# CCG2 register map
File version: 1.0
CPU: CM0 r1p0, little endian, no MPU, no FPU, 2 interrupt priority bits
Registers are 32-bit, read-write, reset 0x0 unless marked. A register's access mark holds for its fields unless they carry their own. Offsets are from the block's base; [hi:lo] are bit positions; {n}, {i} and the like mark numbered series; 'fields as' and 'values as' point back to an identical list; <NAME> marks a mode.

## USBPD (part 1 of 2)
Base 0x40080000
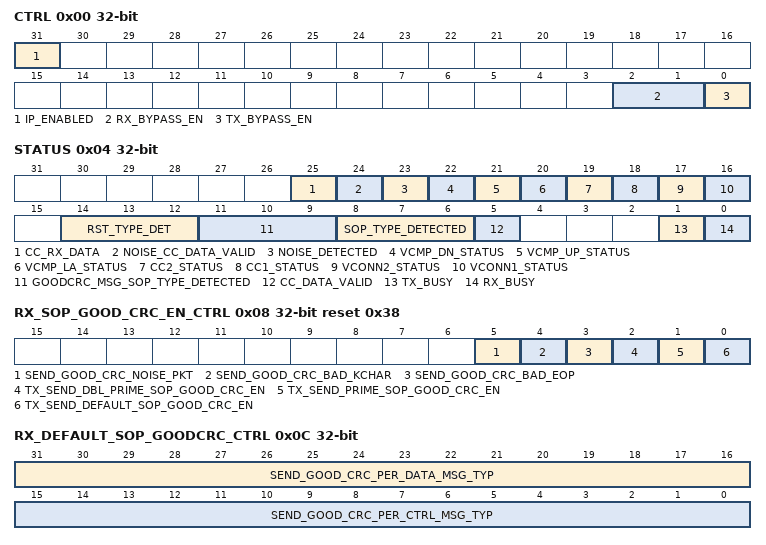
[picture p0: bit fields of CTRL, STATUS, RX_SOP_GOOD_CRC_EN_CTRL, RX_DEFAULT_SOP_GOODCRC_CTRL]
0x00 CTRL — Generic control register.
  [31] IP_ENABLED — IP enabled ('1') or not ('0'). "0" Resets the IP. The reset is an async reset. Note that when the IP is disabled, all the interrupt sources are also disabled.
  [2:1] RX_BYPASS_EN — Setting this register will bypass 5b/4b, CRC.
    0=NO_BYPASS; 1=RX_SOP_ALLIGN; 2=NO_RX_SOP_ALLGN
  [0] TX_BYPASS_EN — Setting this register will bypass 5b/4b, CRC.
0x04 STATUS — Generic status register.
  [25] CC_RX_DATA ro — This status bit shows the RX Data comparator output from s8usbpd_cc_top.
  [24] NOISE_CC_DATA_VALID ro — This status bit shows the CC_RX_VALID signal with the noise_detected signal effect. It is raw_cc_rx_valid & !noise_detected.
  [23] NOISE_DETECTED ro — This status shows the noise detection on vcmp_up or vcmp_la or CC RX Line. The source of noise from the comparator is selectable by RX_CC: VCMP_UP_COMP_ENABLE, VCMP_LA_COMP_ENABLE and RX_NOISE_CHECK_ENABLE. The Noise detectition is defined by NOISE_EDGE_COUNT
  [22] VCMP_DN_STATUS ro — This register provides the status of VCMP_DN (wakeup interrupt from deepsleep). Not enabled unless CMP_EN bit is set. Edge: Ra/Rd value changed OR Edge: Rp value changed
  [21] VCMP_UP_STATUS ro — This register provides the status of VCMP_UP (wakeup interrupt from deepsleep). Not enabled unless CMP_EN bit is set. Edge: Ra/Rd value changed {VCMP_UP, VCMP_DN}: 00: Ra connected 01: Rd connected 11: Nothing connected (float) OR Edge: Rp value changed {VCMP_UP, VCMP_DN}: 00: Default Rp broadcast 01: 1.5A Rp broadcast 11: 3.0A Rp broadcast
  [20] VCMP_LA_STATUS ro — This register provides the status CC_LINE_ACTIVITY (wakeup interrupt from deepsleep).
  [19] CC2_STATUS ro — CC2 status (wakeup interrupt from deepsleep) 1: CC2 attached 0: CC2 detached
  [18] CC1_STATUS ro — CC1 status (wakeup interrupt from deepsleep) 1: CC1 attached 0: CC1 detached
  [17] VCONN2_STATUS ro — The status of either vconn2_changed or cmp_out depending on the selection defined in DEBUG_CC_0.VCONN2_CMP_OUT_SEL VCONN2 status/cmp_out (wakeup interrupt from deepsleep) If VCONN2_CMP_SEL = 0 1: VCONN1 > 2.7V 0: VCONN1 < 2.7V If VCONN2_CMP_SEL = 0 1: cmp_out is 1 0: cmp_out is 0
  [16] VCONN1_STATUS ro — VCONN1 status (wakeup interrupt from deepsleep) 1: VCONN1 > 2.7V 0: VCONN1 < 2.7V
  [14:12] RST_TYPE_DET ro — RST Type detected:
    1=HARD_RESET_RCVD; 2=CABLE_RESET_RCVD; 3=RSVD1_RESET_RCVD; 4=RSVD2_RESET_RCVD
  [11:9] GOODCRC_MSG_SOP_TYPE_DETECTED ro — GoodCrc Message SOP type detected: At the start of every packet, INTR.RCV_GOODCRC_MSG_COMPLETE status is evaluated, if its reset, then this register will be updated with the new packet SOP value.
    0=NO_SOP_GOODCRC_RCVD; 1=DEFAULT_SOP_GOODCRC_RCVD; 2=PRIME_SOP_GOODCRC_RCVD; 3=DBL_PRIME_SOP_GOODCRC_RCVD; 4=DBG_PRIME_SOP_GOODCRC_RCVD; 5=DBG_DBL_PRIME_SOP_GOODCRC_RCVD; 6=RSVD1_SOP_GOODCRC_RCVD; 7=RSVD2_SOP_GOODCRC_RCVD
  [8:6] SOP_TYPE_DETECTED ro — Type of SOP detected for the packet stored in the RX SRAM: At the start of every packet, INTR.RCV_PACKET_COMPLETE and INTR.RCV_RST status is evaluated. If both are "0", then this register will be updated with the new packet SOP value. There is no clearing option.
    0=NO_SOP_RCVD; 1=DEFAULT_SOP_RCVD; 2=PRIME_SOP_RCVD; 3=DBL_PRIME_SOP_RCVD; 4=DBG_PRIME_SOP_RCVD; 5=DBG_DBL_PRIME_SOP_RCVD; 6=RSVD1_SOP_RCVD; 7=RSVD2_SOP_RCVD
  [5] CC_DATA_VALID ro — This status bit shows the CC_RX_VALID signal without noise_detected signal. This is the output of the RX comparator and it is not qualified with noise detection logic. 0: No Valid data on the CC line' 1: Valid Data detectd on the CC line
  [1] TX_BUSY ro — Transmitter is currently transmitting a packet or the crc timmer is running
  [0] RX_BUSY ro — Receiver is currently receiving a packet
0x08 RX_SOP_GOOD_CRC_EN_CTRL reset 0x38 — RX SOP Control for sending GoodCRC Message Hardware will wait for programmable IDLE_COUNTER and then send Good Crc Message.
  [5] SEND_GOOD_CRC_NOISE_PKT — Setting this bit will enable sending GoodCrcMsg for packet that has noise during the whole packet. This should be left to default for normal operation.
  [4] SEND_GOOD_CRC_BAD_KCHAR — Setting this bit will enable sending GoodCrcMsg for packet with KCHAR Error. This should be left to default for normal operation.
  [3] SEND_GOOD_CRC_BAD_EOP — Setting this bit will enable sending GoodCrcMsg for packet with Bad EOP. This should be left to default for normal operation.
  [2] TX_SEND_DBL_PRIME_SOP_GOOD_CRC_EN — Setting this bit will enable the TX block to automatically issue a GoodCRC Message when the received packet with dbl prime SOP which has no CRC issue and the packet has been written into SRAM successfully.
  [1] TX_SEND_PRIME_SOP_GOOD_CRC_EN — Setting this bit will enable the TX block to automatically issue a GoodCRC Message when the received packet with prime SOP which has no CRC issue and the packet has been written into SRAM successfully.
  [0] TX_SEND_DEFAULT_SOP_GOOD_CRC_EN — Setting this bit will enable the TX block to automatically issue a GoodCRC Message when the received packet with Dafault SOP which has no CRC issue and the packet has been written into SRAM successfully.
0x0C RX_DEFAULT_SOP_GOODCRC_CTRL — RX Default SOP GoodCRC Control There are two purposes for this register: 1. Transmit Path: When hardware is done transmitting a packet, it will start the RX_CRC_TIMER. The CRC timer should stop on following conditions: 1. Good CRC Received: With Matching Message ID, Matching Header Sop type. 2. Hard Reset on Receive side 3. Soft Reset on Receive Side: 4. Any other message legal in the current firmware state: Condition 1, condition 2: These two conditions are automatically taken care by hardware and CRC timer is stopped. Condition 3, condition 4: Firmware needs to take care of. Firmware can program what legal messages it is expecting in a particular state and hardware will stop its counter. E.G: If firmware wants the transmit logic to stop its CRC counter and not retry the packet on reception of these following messages: � Soft Reset Control Message: Message Type 1101 � Get Source Cap Control Message: Message Type 0111 � Vendor Defined Data Message: Message Type 1111 Then in that case firmware will program RX_DEFAULT_SOP_GOODCRC_CTRL to: 8000_2080 (Bit 7th, bit 13th and bit 31st) Hardware will stop the timers on reception of these packets and will also automatically send GoodCRC message to these messages if the proper auto bit is set in RX_SOP_GOOD_CRC_EN_CTRL. Other messages received will be logged in RX_Memory but Good CRC will not be returned or timer will not be stopped. 2. Receive Path: Based on one hot encoding of RX_DEFAULT_SOP_GOODCRC_CTRL mapped to message type field in the incoming header, Good CRC will be returned automatically if the correct RX_SOP_GOOD_CRC_EN_CTRL bit is set.
  [31:16] SEND_GOOD_CRC_PER_DATA_MSG_TYP — The Message type of a data message is a 4-bit field. Every bit of this register mapps to the data message types. CPU can used this register to select for which one of the the message types of a data message should hardware send a GOODCRC message.
  [15:0] SEND_GOOD_CRC_PER_CTRL_MSG_TYP — The Message type of a control message is a 4-bit field. Every bit of this register mapps to the control message types. CPU can used this register to select for which one of the the message types of a control message should hardware send a GOODCRC message.
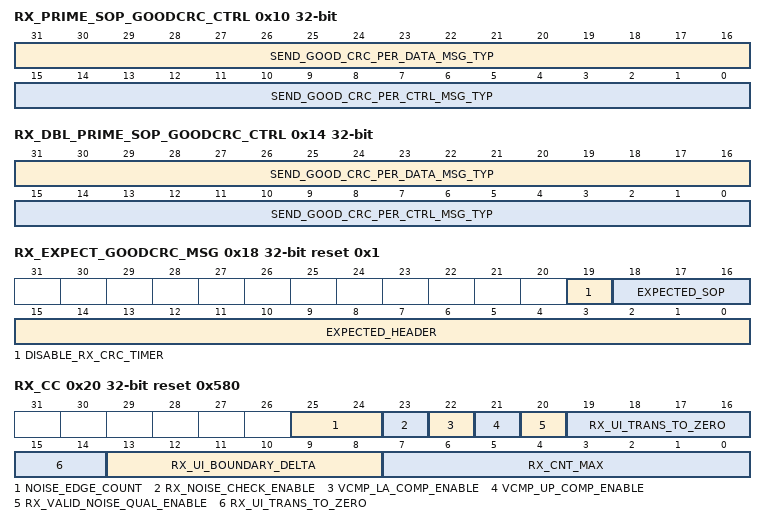
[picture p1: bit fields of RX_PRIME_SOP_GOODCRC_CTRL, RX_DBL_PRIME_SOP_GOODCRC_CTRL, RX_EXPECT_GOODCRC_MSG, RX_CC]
0x10 RX_PRIME_SOP_GOODCRC_CTRL — RX Prime SOP GoodCRC Control
  fields as RX_DEFAULT_SOP_GOODCRC_CTRL
0x14 RX_DBL_PRIME_SOP_GOODCRC_CTRL — RX DBL Prime SOP GoodCRC Control
  fields as RX_DEFAULT_SOP_GOODCRC_CTRL
0x18 RX_EXPECT_GOODCRC_MSG reset 0x1 — RX Excepted good CRC message to stop the CRC timers
  [19] DISABLE_RX_CRC_TIMER — FW should toggle this bit before commiting a new packet to be transferred from TX_MEM. 0: Don�t disable the RX CRC count down 1: Disable the RX CRC count down. FW can disable the RX CRC timer whenever it detects the required condition.
  [18:16] EXPECTED_SOP — The expected SOP of GoodCRC Messgae on the RX side.
    0=EXP_RESERVED; 1=EXP_DEFAULT_SOP_RCVD; 2=EXP_PRIME_SOP_RCVD; 3=EXP_DBL_PRIME_SOP_RCVD; 4=EXP_DBG_PRIME_SOP_RCVD; 5=EXP_DBG_DBL_PRIME_SOP_RCVD; 6=EXP_RSVD1_SOP_RCVD; 7=EXP_RSVD2_SOP_RCVD
  [15:0] EXPECTED_HEADER — The expected GoodCRC Messgae Header on the RX side. The expected message ID is handled by Firmware. The CRC timer will stop on: 1: On the reception of GoodCRC Messegae with good CRC32 where its header matches with this register AND 2: The SOP of the GoodCRC Messgae matches with the EXPECTED_SOP.
0x1C RX_GOODCRC_MSG — The 2-Byte Header of the received GoodCRC Message
  [15:0] HEADER ro — The INTR.RCV_GOODCRC_MSG_COMPLETE interrupt indicates the 2-Byte header for GoodCRC message is received and stored in this registers. GOODCRC_MSG_SOP_TYPE_DETECTED contains the SOP type for the GoodCRC MSG. At the start of every packet, INTR.RCV_GOODCRC_MSG_COMPLETE status is evaluated, if its reset, then only a new packet will be written else new packet will be dropped.
0x20 RX_CC reset 0x580 — The Receive C-Connect registers
  [25:24] NOISE_EDGE_COUNT — Defines number of noise edges that causes noise detection.
    0=THREE_TRANS_TRIG; 1=FOUR_TRANS_TRIG; 2=FIVE_TRANS_TRIG; 3=SIX_TRANS_TRIG
  [23] RX_NOISE_CHECK_ENABLE — Enables noise check on rx line.
  [22] VCMP_LA_COMP_ENABLE — Enables noise check on vcmp_la comparator.
  [21] VCMP_UP_COMP_ENABLE — Enables noise check on vcmp_up comparator.
  [20] RX_VALID_NOISE_QUAL_ENABLE — Setting this bit will qualify cc_rx_valid with noise detection logic.
  [19:14] RX_UI_TRANS_TO_ZERO — This value should be set to half of shortest pulse width on RX line. This will help detection of clock boundary after frequency calculation is complete during preamble.
  [13:8] RX_UI_BOUNDARY_DELTA — This value helps to define the 71% value of the UI. The Hardware automatically calculates the 75% location. The value of this register determines the number of RX_CLK between 71% & 75% location. The default value of 0x5 is based on RX_CLK running at 24 Mhz. For 12 Mhz CLK_RX operations, set the value to 0x3
  [7:0] RX_CNT_MAX — This value is internally multiplied by 4. The 4X value when multiplied by the period of CLK_RX defines the maximum clock period. This value is used to cause the RX state machine to return to idle state if no transitions are detected. The default value of 0x80 is based on CLK_RX=24 Mhz For 12 Mhz CLK_RX operations, set the value to 0x40
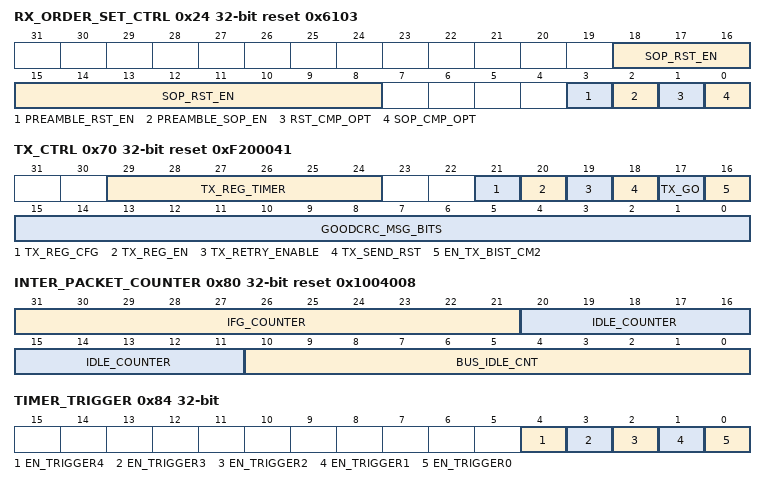
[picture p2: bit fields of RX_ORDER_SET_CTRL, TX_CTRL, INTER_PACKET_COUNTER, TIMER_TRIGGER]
0x24 RX_ORDER_SET_CTRL reset 0x6103 — Receive SOPs and RSTs order set control
  [18:8] SOP_RST_EN — Host Mode: F/W can enable SOP, SOP�, SOP� and Hard Reset Detection. Device Mode: F/W should enable only SOP and Hard Reset Detection. Cable Mode: Either SOP� or SOP� based on VCONN, Hard Reset and Cable Reset should be enabled.
    1=EN_DEFAULT_SOP_DET; 2=EN_PRIME_SOP_DET; 4=EN_DBL_PRIME_SOP_DET; 8=EN_DEBUG_PRIME_SOP_DET; 16=EN_DEBUG_DBL_PRIME_DET; 32=EN_RX_CABLE_RESET_DET; 64=EN_RX_HARD_RESET_DET; 0x100=EN_RESERVED1; 0x400=EN_RESERVED2
  [3] PREAMBLE_RST_EN — This register is used to enable/disdable 16-bit preamble detection for RST detection. 0: RST Detection: RST logic detection 1: RST detection: Preamble(16-bit)+ RST logic detection
  [2] PREAMBLE_SOP_EN — This register is used to enable/disdable 16-bit preamble detection for SOP detection. 0: SOP Detection: SOP logic detection 1: SOP detection: Preamble(16-bit)+ SOP logic detection
  [1] RST_CMP_OPT — This register is used for Cable RST, Hard RST and RX_RESERVED1/2_ORDER_SET(if configure for RST) order set detection. It is recommended that CPU program this register to 1 ( 4 out of 4 option). 0: Compare 3 out of 4 order sets 1: Compare 4 out of 4 order sets
  [0] SOP_CMP_OPT — This register is used for SOP, SOP',SOP'", DEBUG SOP', DEBUG SOP" and RX_RESERVED1/2_ORDER_SET(if configured for SOP) oder set detection. It is recommended that CPU program this register to 1 ( 4 out of 4 option). 0: Compare 3 out of 4 order sets 1: Compare 4 out of 4 order sets
0x28 RX_RESERVED1_ORDER_SET — Receive Reserved1 order set
  [31:0] RX_RESERVED1_OS — Receive Reserved1 order set This Register Can also be used for SOP' and SOP"" [15:0] Can also be used for Transmiting GoddCRC Message to SOP' [31:16] Can also be used for Transmiting GoddCRC Message to SOP" This register constains the Transmit GoodCRC Message Header except the MessageID which Is handled by Hardware. [11:9] Message ID (This is handled by HardWare)
0x2C RX_RESERVED2_ORDER_SET — Receive Reserved2 order set
  [19:0] RX_RESERVED2_OS
{0x30+4i} RX_MEM_DATA{i} (i=0..7) — RX SRAM Data The memory for the RX USB power controller is a 32 byte SRAM. Address map for this Memory is: 0x0050: The Rx Header 0x0054:0x006C: The RX Data Object Any access to address space 0x0050 - 0x006C will map to SRAM address x0-x15
  [31:0] DATA ro — Header/Data information in the receive SRAM. SOP type is stored in STATUS.SOP_TYPE_DETECTED register. The CPU should perform one read to register address 0x0030 to get the Rx Header(16-bit). The upper 16-bit of the address 0x0030 should be ignored. CPU should extract the 4-byte count from the Rx Header and perform the proper number of read transactions. STATUS.SOP_TYPE_DETECTED contains the SOP type for the packet in the RX SRAM. At the start of every packet, INTR.RCV_PACKET_COMPLETE and INTR.RCV_RST status is evaluated, if its reset, then only a new packet will be written else new packet will be dropped.
{0x50+4i} TX_MEM_DATA{i} (i=0..7) — TX SRAM Data The memory for the TX USB power controller is a 32 byte SRAM. Address map for this Memory is: 0x0030: The Tx Header 0x0034:0x004C: The TX Data Object Any access to address space 0x0030 - 0x004C will map to SRAM address x0-x15
  [31:0] DATA — Header/Data information in the transmitter SRAM. SOP/CRC/EOP will be appened by HW. The CPU is required to program the TX Header into lower 16-bit of register address 0x0050. The data read(Tx Header, 16-bit) from this address provides the number of 4-bytes required to be transmitted. If the byte count is zero in the Tx Header, then no more read will be issued to SRAM.
0x70 TX_CTRL reset 0xF200041 — TX Control
  [29:24] TX_REG_TIMER — The time needed to enable the TX regulator before transmission. The counter runs on CLK_TX_HALF(600Khz)
  [21] TX_REG_CFG — 0: Hardware controlling of TX regulator Enable is disabled. CPU can fully control the TX regulator enable by using TX_REG_EN. 1: Hardware controlling the TX regulator Enable is enabled. In this case, CPU can only set the regulator enable to one by setting TX_REG_EN
  [20] TX_REG_EN — Enable the transmitter regulator
  [19] TX_RETRY_ENABLE — Enable transmit retry. Hardware clears this bit once the command is accepted and processing has begun. CPU should increment the retry counter in firmware once TX_PACKET_DONE interrupt is detected by CPU. CPU should set the Retry_Enable bit again if another retry is expected. (CPU should have approximately 750 usec to set this bit). The following operation is recommneded to FW: � FW maintains the retry counter � FW writes a packet in TX_Memory. � FW checks its retry counter and if its >0 , sets the retry enable bit. � FW sets the TX_GO. � HW sends the packet and starts CRC_Timer if enabled. � On Expiry of CRC_timer, HW retries the packet if retry enable bit was set and then HW auto clears that bit. � HW will start the CRC_timer again. � FW in parallel would have received the CRC_TIMER expiry interrupt� FW will decrement its retry counter and if retry counter is still >0, then it will set the retry enable again ( F/W will have approx 1 msec to do this after getting previous CRC timer expiry interrupt)
  [18] TX_SEND_RST — Send a Reset over the link. Write a 1 to this bit to cause the transmitter to send a Hard Reset or Cable Reset(TX_HARD_CABLE_ORDER_SET register) over the link. Hardware clears this bit once the command is accepted and processing has begun. If TX_SEND_RST is set and there is a ongoing receive packet, the Reset Sequqnce wont be sent and the COLLISION_TYPE4 interrupt will be set. In this case, hardware clears the TX_SEND_RST. Before settting this FW should check: INTR0->RX_GOOD_PKT && STATUS->DATA_VALID == 0
  [17] TX_GO — TX_GO causes a packet to be sent. FW can send GoodCrcMsg by storing it in the TX SRAM and use TX_GO to send it. Writing a 1 to this bit to cause the message stored in the SRAM Memory to be sent. Hardware clears this bit once the command is accepted and processing has begun. If TX_GO is set and there is a ongoing receive packet, the TX packet wont be sent and the COLLISION_TYPE1 interrupt will be set. In this case, hardware clears the TX_GO. Before setting this FW should check: INTR0->RX_GOOD_PKT && STATUS->DATA_VALID == 0
  [16] EN_TX_BIST_CM2 — Setting the EN_TX_BIST_CM2 to "1" will start the transmision of Bist Carrier Mode 2 pattern. FW must manually set TX_CTRL.TX_REG_EN to "1" before setting this register(EN_TX_BIST_CM2) The TX_GO register is not required to be set for this mode.
  [15:0] GOODCRC_MSG_BITS — For SOP Only. This register constains the Transmit GoodCRC Message Header except the MessageID which Is handled by Hardware. [11:9] Message ID (This is handled by HardWare)
0x74 TX_SOP_ORDER_SET reset 0x8E318 — Transmit SOP order set
  [19:0] TX_SOP_OS — Transmit SOP order Set use in transmit except GoodCrcMsg
0x78 TX_HARD_CABLE_ORDER_SET reset 0xE7393 — Transmit Hard/Cable reset order set
  [19:0] TX_RESET_OS — Transmit Hard/Cable Reset order Set. Default: Hard Reset Value 0xE7393 Cable Reset Value: 0xE0F8C
0x7C CRC_COUNTER — The CRC timer counters/Bypass configuration Counters used for the timmers needed by this IP
  [15:0] CRC_COUNTER — If TX_BYPASS_EN = 0: This counter will run on TX_CLK/2 (PD bit period) clock. This counter is used for CRCReceiveTimer(tReceive)/BISTReceiveErrorTimertBistReceive 0: Counter is disabled. Hardware will NOT wait for the CRC_COUNTER to expire. Other: Hardware will wait for the CRC_COUNTER to expire. Once the CRC_COUNTER reaches zero and no Valid CoodCRC message is not received, The CRC_RX_TIMER_EXP interrupt gets set. If TX_BYPASS_EN = 1: [10:0]: Total number of bits
0x80 INTER_PACKET_COUNTER reset 0x1004008 — The Inter Packet counters Counters used for IDLE/IFG and by this IP All the timers/counters have a resolution of 1 UI (Unit Interval) of a Bit. If transmit rate is 300Khz, then each count will tick for 3.33 usec.
  [31:21] IFG_COUNTER — END OF ANY RX ON CC-LINE On any RX Packet, this counter will start at end of RX Packet and will reset on Start of RX Packet. This register can be again used to comply with Interpacket Gap (25 usec + end of IDLE detection(12 usec)). CPU after seeing no activity on the bus can immedeately set the TX_GO/TX_SEND_RST bit and this register will make sure that we don't violate any interpacket gap requirement. 0: Counter is disabled.
  [20:11] IDLE_COUNTER — RX -> AUTO_GOODCRC_RESPONSE This counter specifies how long the HW should wait after the end of RX packet to send GoodCRC message. This can be used to comply with interpacket gap of 25usec. 0: Counter is disabled. Hardware will issue goodcrc message if needed after end of the RX Packet
  [10:0] BUS_IDLE_CNT — USED FOR TX->TX This register is used by DUT to create gap between two back to back transmit packets. For example: For a DFP application if DFP wants to send Hard Reset after a valid packet, then this register could be used for complying with Inter-Packet Gap of 25 usec specified by spec. In cable application, after sending Good CRC handshake for request from DUT, this register could be used to comply with 750usec requirement of cable response after sending Good CRC pkt.
0x84 TIMER_TRIGGER — The trigger enable registers The tr_out[4:0] pins of this IP will be connected to the tr_in pin of m0s8tcpwm_ver2 IP at the full chip. The mapping of the these signals is SoC depended and it is defined in SAS.
  [4] EN_TRIGGER4 — 1: The tr_out[4] pin of the IP will toggle on the transmission of the last Bit of EOP (Additional trigger for starting some different timer). 0: The toggling of the tr_out[4] pin of the IP is disabled.
  [3] EN_TRIGGER3 — 1: The tr_out[3] pin of the IP will toggle on the reception of EOP for any message (Example: RX Hard Reset/ BIST) 0: The toggling of the tr_out[3] pin of the IP is disabled.
  [2] EN_TRIGGER2 — 1: The tr_out[2] pin of the IP will toggle on the reception of EOP for any message with Valid CRC (Excludes the message types specified in the RX_CTL register) 0: The toggling of the tr_out[2] pin of the IP is disabled.
  [1] EN_TRIGGER1 — 1: The tr_out[1] pin of the IP will toggle on the reception of EOP for any message with Valid CRC (Includes Good Crc Message) 0: The toggling of the tr_out[1] pin of the IP is disabled.
  [0] EN_TRIGGER0 — 1: The tr_out[0] pin of the IP will toggle on the transmission of the last Bit Of EOP. 0: The toggling of the tr_out[0] pin of the IP is disabled.
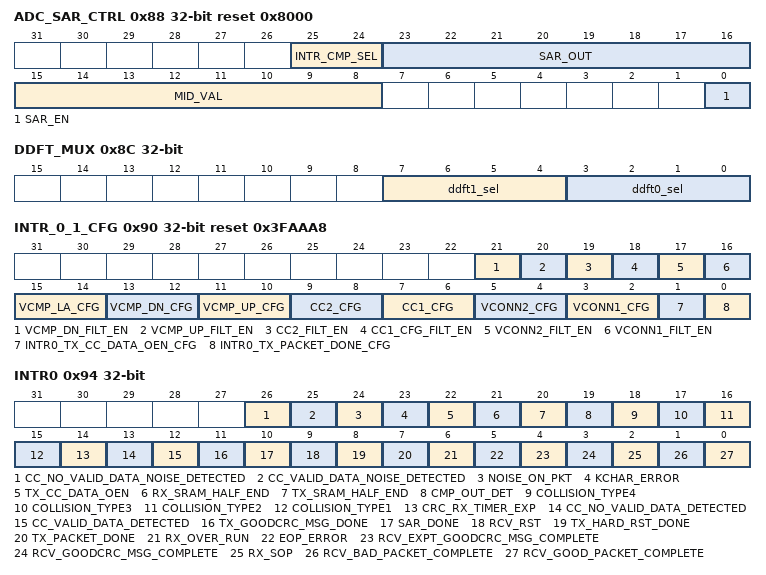
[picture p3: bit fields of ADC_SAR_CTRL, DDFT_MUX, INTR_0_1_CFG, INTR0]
0x88 ADC_SAR_CTRL reset 0x8000 — ADC SAR Control Register General Purpose voltgae measurement, Temperature Sceining
  [25:24] INTR_CMP_SEL wo — This register selects which edge of cmp_out pin of the s8usbpd_adc_top should be used to generate INT0.CMP_OUT_DET
    0=DIS_INT0_CMP_OUT_DET; 1=EN_RISE_EDGE; 2=EN_FALL_EDGE; 3=EN_BOTH_EDGE
  [23:16] SAR_OUT ro — ADC output resistance value Stored 8-bit ADC value after the ID Pin voltage is sampled.
  [15:8] MID_VAL — ADC starting mid value
  [0] SAR_EN write-1-sets — Setting this bit will enable the HW SAR logic. Once the SAR_EN is one, Hardware will update the SAR_OUT register after 8 cycles of clk_sar and clear this register.
0x8C DDFT_MUX — DDFT Selections
  [7:4] ddft1_sel — 0: DDFT1 from previous m0s8usbpd instantiation if any 1: cc2_attach_det 2: cc1_attach_det 3: clk_rx 4: cc_tx_data 5: cc_core_tx_data 6: cc_rx_bit_en 7: raw_cc_rx_valid 8: rx_eop 9: rx_sop 10: noise_detected 11: noise_on_pkt 12: vcmp_up 13: vcmp_la
  [3:0] ddft0_sel — 0: DDFT0 from previous m0s8usbpd instantiation if any 1: vcmp_up 2: vcmp_dn 3: vcmp_la 4: vconn1_det 5: vconn2_det 6: clk_tx 7: cc_tx_data_valid 8: cc_tx_data_eop 9: cc_ctrl_tx_en 10: cc_rx_data 11: cc_core_rx_data 12: noise_cc_rx_valid
0x90 INTR_0_1_CFG reset 0x3FAAA8 — Wakeup Interrupts edge and filter configuration and Intr0 configuration
  [21] VCMP_DN_FILT_EN — Filtering the VCMP_DNfrom s8usbpd.: 0: No Filtering 1: Enable 3 cycles of clk_lf filtering
  [20] VCMP_UP_FILT_EN — Filtering the VCMP_UP from s8usbpd.: 0: No Filtering 1: Enable 3 cycles of clk_lf filtering
  [19] CC2_FILT_EN — Filtering the CC2_ATTACH from s8usbpd.: 0: No Filtering 1: Enable 3 cycles of clk_lf filtering
  [18] CC1_CFG_FILT_EN — Filtering the CC1_ATTACH from s8usbpd.: 0: No Filtering 1: Enable 3 cycles of clk_lf filtering
  [17] VCONN2_FILT_EN — Filtering the VCONN2_DET from s8usbpd.: 0: No Filtering 1: Enable 3 cycles of clk_lf filtering
  [16] VCONN1_FILT_EN — Filtering the VCONN1_DET from s8usbpd.: 0: No Filtering 1: Enable 3 cycles of clk_lf filtering
  [15:14] VCMP_LA_CFG — Edge detect2 positive/negative enable/disable
    0=POS_EDG_DIS_NEG_EDG_DIS; 1=POS_EDG_DIS_NEG_EDG_EN; 2=POS_EDG_EN_NEG_EDG_DIS; 3=POS_EDG_EN_NEG_EDG_EN
  [13:12] VCMP_DN_CFG — Edge detect2 positive/negative enable/disable
    values as VCMP_LA_CFG
  [11:10] VCMP_UP_CFG — Edge detect2 positive/negative enable/disable
    values as VCMP_LA_CFG
  [9:8] CC2_CFG — Edge detect2 positive/negative enable/disable
    values as VCMP_LA_CFG
  [7:6] CC1_CFG — Edge detect2 positive/negative enable/disable
    values as VCMP_LA_CFG
  [5:4] VCONN2_CFG — Edge detect2 positive/negative enable/disable
    values as VCMP_LA_CFG
  [3:2] VCONN1_CFG — Edge detect2 positive/negative enable/disable
    values as VCMP_LA_CFG
  [1] INTR0_TX_CC_DATA_OEN_CFG — Source of INTR0.TX_CC_DATA_OEN 0: CC Output Enable de-assert 1: TX EOP
  [0] INTR0_TX_PACKET_DONE_CFG — Source of INTR0.TX_PACKET_DONE 0: TX EOP 1: CC Output Enable de-assert
0x94 INTR0 — INTR0 Cause
  [26] CC_NO_VALID_DATA_NOISE_DETECTED write-1-clears — Valid Data got de-asserted on the CC line based on the noise_detected
  [25] CC_VALID_DATA_NOISE_DETECTED write-1-clears — Valid Data detected on the CC line based on the noise_detected
  [24] NOISE_ON_PKT write-1-clears — Detected noise during reception of Packet.
  [23] KCHAR_ERROR write-1-clears — Received Symbol wasn't a valid K-Code.
  [22] TX_CC_DATA_OEN write-1-clears — TX Data Output Enable of TX-CC is de-asserted
  [21] RX_SRAM_HALF_END write-1-clears — Hardware has passed writing the data to Half or End of the RX SRAM Memory Location
  [20] TX_SRAM_HALF_END write-1-clears — Hardware has passed reading the data from Half or End of the TX SRAM Memory Location
  [19] CMP_OUT_DET write-1-clears — cmp_out pin of s8usbpd_adc_top changed based on the ADC_SAR_CTRL.INTR_CMP_SEL
  [18] COLLISION_TYPE4 write-1-clears — Transmit Collision Type4: Collsion is detected due to TX_SEND_RST/RX has occurred
  [17] COLLISION_TYPE3 write-1-clears — Transmit Collision Type3: Collsion is detected due to TX-GoodCrc_MSG/RX has occurred
  [16] COLLISION_TYPE2 write-1-clears — Transmit Collision Type2: Collsion is detected due to TX-RETRY/RX has occurred
  [15] COLLISION_TYPE1 write-1-clears — Transmit Collision Type1: Collsion is detected Due to TX_GO(TX Data)/RX has occurred
  [14] CRC_RX_TIMER_EXP write-1-clears — CRCReceiveTimer has expired
  [13] CC_NO_VALID_DATA_DETECTED write-1-clears — Valid Data got de-asserted on the CC line
  [12] CC_VALID_DATA_DETECTED write-1-clears — Valid Data detected on the CC line
  [11] TX_GOODCRC_MSG_DONE write-1-clears — A GoodCRC message was transmitted.
  [10] SAR_DONE write-1-clears — Marks Completion of SAR conversion at the end of 8 cycles of clk_sar when SAR_EN is "1"
  [9] RCV_RST write-1-clears — Received a REST. FW should read RST_TYPE for the type of RST. Firmware should process this interrupt according to the USB-PD spec. Hardware does not process the Reset packets other than providing this interrupt. Hardware will stop processing any pending transmit packet until this interrupt is cleared.
  [8] TX_HARD_RST_DONE write-1-clears — Transmitter done sending Hard Reset
  [7] TX_PACKET_DONE write-1-clears — Transmitter done sending data packet.
  [6] RX_OVER_RUN write-1-clears — New data was received when the RCV_PACKET_COMPLETE is not cleared by CPU.
  [5] EOP_ERROR write-1-clears — Received Symbol wasn't a valid EOP K-Code. It should be evaludated after RCV_PACKET_COMPLETE.
  [4] RCV_EXPT_GOODCRC_MSG_COMPLETE write-1-clears — Receive the expted GoodCRC-message based on the RX_EXPECT_GOODCRC_MSG register. Indicates that the expected GoodCRC-message is stored in RX_GOODCRC_MSG register. The received expected GoodCRC-message had no CRC error and no KCHAR error This interrupt gets evaluated on end of every packet (except hard reset) and needs to be cleared. For Correct usage of the interrupt: This interrupt should be cleared on every packet if set. RCV_GOOGCRC_MSG_COMPLETE should be cleared before new good crc response comes else RX_GOODCRC_MSG will not get updated.
  [3] RCV_GOODCRC_MSG_COMPLETE write-1-clears — Receive GoodCRC-message Complete. Indicates that the GoodCRC-message is stored in RX_GOODCRC_MSG register. The received GoodCRC-message had no CRC error and no KCHAR error
  [2] RX_SOP write-1-clears — Receive a SOP. FW should read SOP_TYPE_DETECTED for the SOP type
  [1] RCV_BAD_PACKET_COMPLETE write-1-clears — Receive a Bad non-GoodCRC-message Data Packet Complete. Indicates that the Receive Packet has been received in its entirety. The received packet had CRC or KCHAR error. If this interrupt is not cleared, then the new data will be written into RX SRAM.
  [0] RCV_GOOD_PACKET_COMPLETE write-1-clears — Receive a Good non-GoodCRC-message Data Packet Complete. Indicates that the Receive Packet has been received in its entirety. The received packet had no CRC and no KCHAR error. If this interrupt is not cleared, then RX_OVER_RUN will be set on the next new data and the new data won't be written into RX SRAM.
